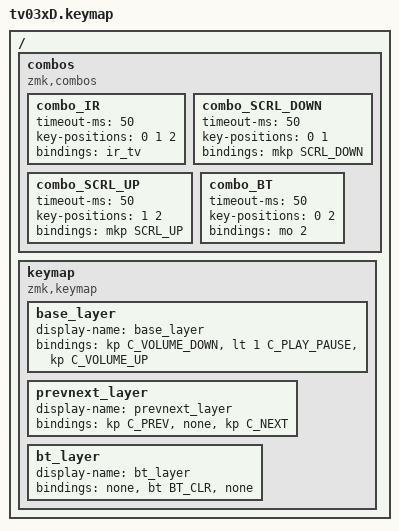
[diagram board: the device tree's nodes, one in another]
#include <behaviors.dtsi>
#include <dt-bindings/zmk/keys.h>
#include <dt-bindings/zmk/bt.h>
#include <dt-bindings/zmk/mouse.h>


#include <behaviors/ir_tv.dtsi> // include for the ceasar reference


/ {    
    combos {
        compatible = "zmk,combos";
        
        combo_IR {
            timeout-ms = <50>;
            key-positions = <0 1 2>;
            bindings = <&ir_tv>;
        };
        combo_SCRL_DOWN {
            timeout-ms = <50>;
            key-positions = <0 1 >;
            bindings = <&mkp SCRL_DOWN>;
        };
        combo_SCRL_UP {
            timeout-ms = <50>;
            key-positions = <1 2>;
            bindings = <&mkp SCRL_UP>;
        };
        combo_BT {
            timeout-ms = <50>;
            key-positions = <0 2>;
            bindings = <&mo 2>;
        };
    };
    
    keymap {
        compatible = "zmk,keymap";
            
        base_layer {
            display-name = "base_layer";
            bindings = <
                &kp C_VOLUME_DOWN &lt 1 C_PLAY_PAUSE &kp C_VOLUME_UP
            >;
        }; 
        
        prevnext_layer {
            display-name = "prevnext_layer";
            bindings = <
                &kp C_PREV &none &kp C_NEXT
            >;
        }; 
        
        bt_layer {
            display-name = "bt_layer";
            bindings = <
                &none &bt BT_CLR &none
            >;
        }; 
    };
};
